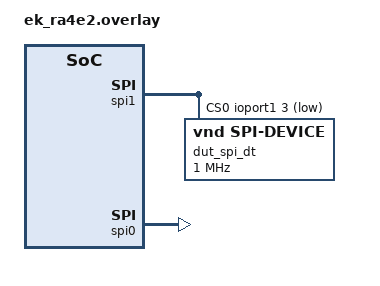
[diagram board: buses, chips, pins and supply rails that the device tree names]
/*
 * Copyright (c) 2025 Renesas Electronics Corporation
 * SPDX-License-Identifier: Apache-2.0
 */

&pinctrl {
	spi1_default: spi1_default {
		group1 {
			/* MISO MOSI RSPCK */
			psels = <RA_PSEL(RA_PSEL_SPI, 1, 0)>,
				<RA_PSEL(RA_PSEL_SPI, 1, 1)>,
				<RA_PSEL(RA_PSEL_SPI, 1, 2)>;
		};
	};
};

&spi1 {
	rx-dtc;
	tx-dtc;
	status = "okay";
	pinctrl-0 = <&spi1_default>;
	pinctrl-names = "default";
	cs-gpios = <&ioport1 3 GPIO_ACTIVE_LOW>;
	interrupts = <92 1>, <93 1>, <94 1>, <95 1>;
	interrupt-names = "rxi", "txi", "tei", "eri";

	dut_spi_dt: test-spi-dev@0 {
		compatible = "vnd,spi-device";
		reg = <0>;
		spi-max-frequency = <1000000>;
	};
};

dut_spis: &spi0 {
	rx-dtc;
	tx-dtc;
	status = "okay";
};
